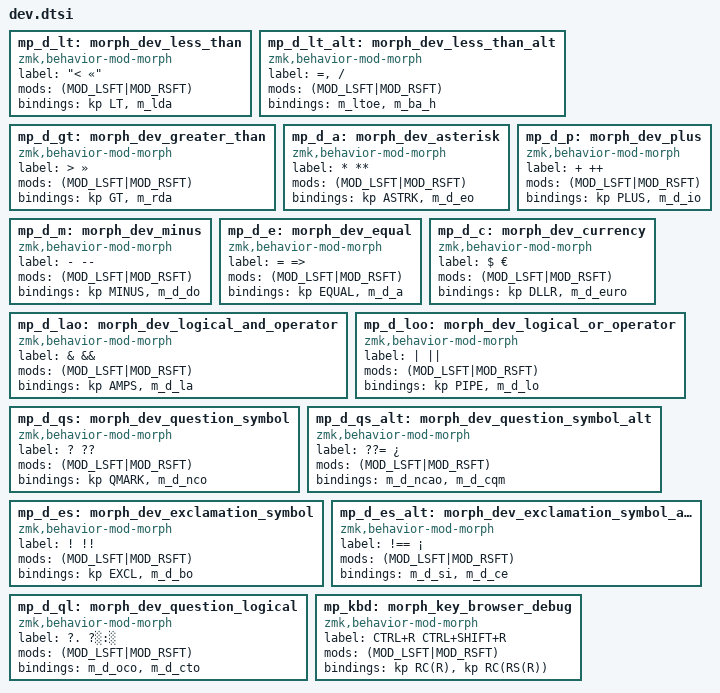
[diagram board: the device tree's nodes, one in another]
mp_d_lt: morph_dev_less_than {
    compatible = "zmk,behavior-mod-morph";
    label = "< «";
    #binding-cells = <0>;
    mods = <(MOD_LSFT|MOD_RSFT)>;
    bindings = <&kp LT>, <&m_lda>;
};

mp_d_lt_alt: morph_dev_less_than_alt {
    compatible = "zmk,behavior-mod-morph";
    label = "<= </>";
    #binding-cells = <0>;
    mods = <(MOD_LSFT|MOD_RSFT)>;
    bindings = <&m_ltoe>, <&m_ba_h>;
};

mp_d_gt: morph_dev_greater_than {
    compatible = "zmk,behavior-mod-morph";
    label = "> »";
    #binding-cells = <0>;
    mods = <(MOD_LSFT|MOD_RSFT)>;
    bindings = <&kp GT>, <&m_rda>;
};

mp_d_a: morph_dev_asterisk {
    compatible = "zmk,behavior-mod-morph";
    label = "* **";
    #binding-cells = <0>;
    mods = <(MOD_LSFT|MOD_RSFT)>;
    bindings = <&kp ASTRK>, <&m_d_eo>;
};

mp_d_p: morph_dev_plus {
    compatible = "zmk,behavior-mod-morph";
    label = "+ ++";
    #binding-cells = <0>;
    mods = <(MOD_LSFT|MOD_RSFT)>;
    bindings = <&kp PLUS>, <&m_d_io>;
};

mp_d_m: morph_dev_minus {
    compatible = "zmk,behavior-mod-morph";
    label = "- --";
    #binding-cells = <0>;
    mods = <(MOD_LSFT|MOD_RSFT)>;
    bindings = <&kp MINUS>, <&m_d_do>;
};

mp_d_e: morph_dev_equal {
    compatible = "zmk,behavior-mod-morph";
    label = "= =>";
    #binding-cells = <0>;
    mods = <(MOD_LSFT|MOD_RSFT)>;
    bindings = <&kp EQUAL>, <&m_d_a>;
};

mp_d_c: morph_dev_currency {
    compatible = "zmk,behavior-mod-morph";
    label = "$ €";
    #binding-cells = <0>;
    mods = <(MOD_LSFT|MOD_RSFT)>;
    bindings = <&kp DLLR>, <&m_d_euro>;
};

mp_d_lao: morph_dev_logical_and_operator {
    compatible = "zmk,behavior-mod-morph";
    label = "& &&";
    #binding-cells = <0>;
    mods = <(MOD_LSFT|MOD_RSFT)>;
    bindings = <&kp AMPS>, <&m_d_la>;
};

mp_d_loo: morph_dev_logical_or_operator {
    compatible = "zmk,behavior-mod-morph";
    label = "| ||";
    #binding-cells = <0>;
    mods = <(MOD_LSFT|MOD_RSFT)>;
    bindings = <&kp PIPE>, <&m_d_lo>;
};

mp_d_qs: morph_dev_question_symbol {
    compatible = "zmk,behavior-mod-morph";
    label = "? ??";
    #binding-cells = <0>;
    mods = <(MOD_LSFT|MOD_RSFT)>;
    bindings = <&kp QMARK>, <&m_d_nco>;
};

mp_d_qs_alt: morph_dev_question_symbol_alt {
    compatible = "zmk,behavior-mod-morph";
    label = "??= ¿";
    #binding-cells = <0>;
    mods = <(MOD_LSFT|MOD_RSFT)>;
    bindings = <&m_d_ncao>, <&m_d_cqm>;
};

mp_d_es: morph_dev_exclamation_symbol {
    compatible = "zmk,behavior-mod-morph";
    label = "! !!";
    #binding-cells = <0>;
    mods = <(MOD_LSFT|MOD_RSFT)>;
    bindings = <&kp EXCL>, <&m_d_bo>;
};

mp_d_es_alt: morph_dev_exclamation_symbol_alt {
    compatible = "zmk,behavior-mod-morph";
    label = "!== ¡";
    #binding-cells = <0>;
    mods = <(MOD_LSFT|MOD_RSFT)>;
    bindings = <&m_d_si>, <&m_d_ce>;
};

mp_d_ql: morph_dev_question_logical {
    compatible = "zmk,behavior-mod-morph";
    label = "?. ?░:░";
    #binding-cells = <0>;
    mods = <(MOD_LSFT|MOD_RSFT)>;
    bindings = <&m_d_oco>, <&m_d_cto>;
};

mp_kbd: morph_key_browser_debug {
    compatible = "zmk,behavior-mod-morph";
    label = "CTRL+R CTRL+SHIFT+R";
    #binding-cells = <0>;
    mods = <(MOD_LSFT|MOD_RSFT)>;
    bindings = <&kp RC(R)>, <&kp RC(RS(R))>;
};
